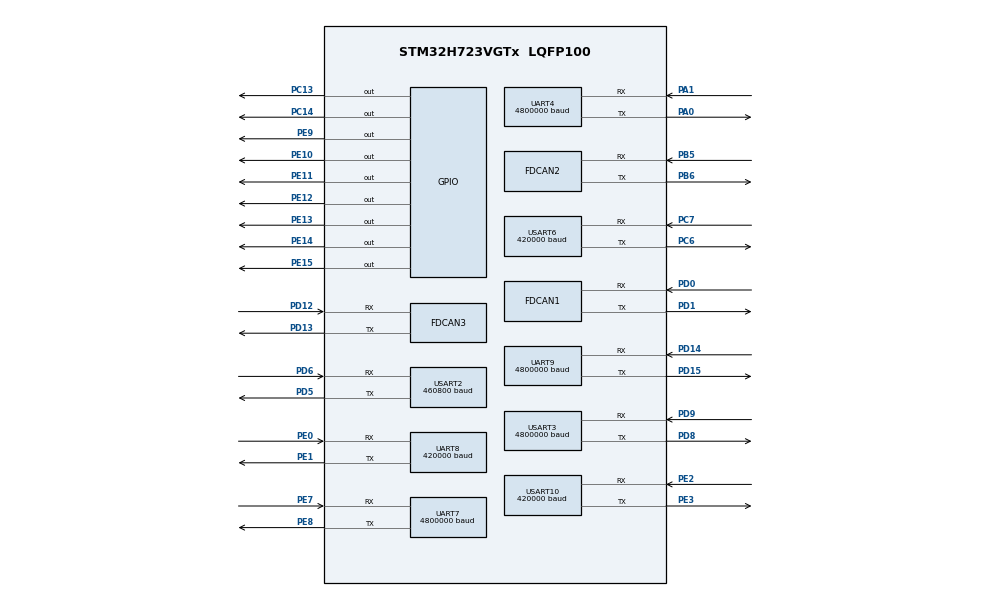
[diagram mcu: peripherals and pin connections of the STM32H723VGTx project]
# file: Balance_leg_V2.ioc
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CORTEX_M7.AccessPermission_Spec=MPU_REGION_FULL_ACCESS
CORTEX_M7.BaseAddress_Spec=0x24000000
CORTEX_M7.CPU_DCache=Enabled
CORTEX_M7.CPU_ICache=Enabled
CORTEX_M7.DisableExec_Spec=MPU_INSTRUCTION_ACCESS_ENABLE
CORTEX_M7.IsBufferable_Spec=MPU_ACCESS_BUFFERABLE
CORTEX_M7.IsCacheable_Spec=MPU_ACCESS_CACHEABLE
CORTEX_M7.IsShareable_Spec=MPU_ACCESS_SHAREABLE
CORTEX_M7.Size_Spec=MPU_REGION_SIZE_512KB
CORTEX_M7.SubRegionDisable_Spec=0x00
CORTEX_M7.TypeExtField_Spec=MPU_TEX_LEVEL1
CORTEX_M7.default_mode_Activation=1
Dma.Request0=USART10_RX
Dma.Request1=USART2_RX
Dma.Request10=UART8_RX
Dma.Request11=UART8_TX
Dma.Request2=USART3_RX
Dma.Request3=USART3_TX
Dma.Request4=UART9_RX
Dma.Request5=UART9_TX
Dma.Request6=UART7_RX
Dma.Request7=UART7_TX
Dma.Request8=UART4_RX
Dma.Request9=UART4_TX
Dma.UART4_RX.8.Direction=DMA_PERIPH_TO_MEMORY
Dma.UART4_RX.8.EventEnable=DISABLE
Dma.UART4_RX.8.FIFOMode=DMA_FIFOMODE_DISABLE
Dma.UART4_RX.8.Instance=DMA1_Stream7
Dma.UART4_RX.8.MemDataAlignment=DMA_MDATAALIGN_BYTE
Dma.UART4_RX.8.MemInc=DMA_MINC_ENABLE
Dma.UART4_RX.8.Mode=DMA_NORMAL
Dma.UART4_RX.8.PeriphDataAlignment=DMA_PDATAALIGN_BYTE
Dma.UART4_RX.8.PeriphInc=DMA_PINC_DISABLE
Dma.UART4_RX.8.Polarity=HAL_DMAMUX_REQ_GEN_RISING
Dma.UART4_RX.8.Priority=DMA_PRIORITY_HIGH
Dma.UART4_RX.8.RequestNumber=1
Dma.UART4_RX.8.SignalID=NONE
Dma.UART4_RX.8.SyncEnable=DISABLE
Dma.UART4_RX.8.SyncPolarity=HAL_DMAMUX_SYNC_NO_EVENT
Dma.UART4_RX.8.SyncRequestNumber=1
Dma.UART4_RX.8.SyncSignalID=NONE
Dma.UART4_TX.9.Direction=DMA_MEMORY_TO_PERIPH
Dma.UART4_TX.9.EventEnable=DISABLE
Dma.UART4_TX.9.FIFOMode=DMA_FIFOMODE_DISABLE
Dma.UART4_TX.9.Instance=DMA2_Stream1
Dma.UART4_TX.9.MemDataAlignment=DMA_MDATAALIGN_BYTE
Dma.UART4_TX.9.MemInc=DMA_MINC_ENABLE
Dma.UART4_TX.9.Mode=DMA_NORMAL
Dma.UART4_TX.9.PeriphDataAlignment=DMA_PDATAALIGN_BYTE
Dma.UART4_TX.9.PeriphInc=DMA_PINC_DISABLE
Dma.UART4_TX.9.Polarity=HAL_DMAMUX_REQ_GEN_RISING
Dma.UART4_TX.9.Priority=DMA_PRIORITY_HIGH
Dma.UART4_TX.9.RequestNumber=1
Dma.UART4_TX.9.SignalID=NONE
Dma.UART4_TX.9.SyncEnable=DISABLE
Dma.UART4_TX.9.SyncPolarity=HAL_DMAMUX_SYNC_NO_EVENT
Dma.UART4_TX.9.SyncRequestNumber=1
Dma.UART4_TX.9.SyncSignalID=NONE
Dma.UART7_RX.6.Direction=DMA_PERIPH_TO_MEMORY
Dma.UART7_RX.6.EventEnable=DISABLE
Dma.UART7_RX.6.FIFOMode=DMA_FIFOMODE_DISABLE
Dma.UART7_RX.6.Instance=DMA1_Stream5
Dma.UART7_RX.6.MemDataAlignment=DMA_MDATAALIGN_BYTE
Dma.UART7_RX.6.MemInc=DMA_MINC_ENABLE
Dma.UART7_RX.6.Mode=DMA_NORMAL
Dma.UART7_RX.6.PeriphDataAlignment=DMA_PDATAALIGN_BYTE
Dma.UART7_RX.6.PeriphInc=DMA_PINC_DISABLE
Dma.UART7_RX.6.Polarity=HAL_DMAMUX_REQ_GEN_RISING
Dma.UART7_RX.6.Priority=DMA_PRIORITY_HIGH
Dma.UART7_RX.6.RequestNumber=1
Dma.UART7_RX.6.SignalID=NONE
Dma.UART7_RX.6.SyncEnable=DISABLE
Dma.UART7_RX.6.SyncPolarity=HAL_DMAMUX_SYNC_NO_EVENT
Dma.UART7_RX.6.SyncRequestNumber=1
Dma.UART7_RX.6.SyncSignalID=NONE
Dma.UART7_TX.7.Direction=DMA_MEMORY_TO_PERIPH
Dma.UART7_TX.7.EventEnable=DISABLE
Dma.UART7_TX.7.FIFOMode=DMA_FIFOMODE_DISABLE
Dma.UART7_TX.7.Instance=DMA1_Stream6
Dma.UART7_TX.7.MemDataAlignment=DMA_MDATAALIGN_BYTE
Dma.UART7_TX.7.MemInc=DMA_MINC_ENABLE
Dma.UART7_TX.7.Mode=DMA_NORMAL
Dma.UART7_TX.7.PeriphDataAlignment=DMA_PDATAALIGN_BYTE
Dma.UART7_TX.7.PeriphInc=DMA_PINC_DISABLE
Dma.UART7_TX.7.Polarity=HAL_DMAMUX_REQ_GEN_RISING
Dma.UART7_TX.7.Priority=DMA_PRIORITY_HIGH
Dma.UART7_TX.7.RequestNumber=1
Dma.UART7_TX.7.SignalID=NONE
Dma.UART7_TX.7.SyncEnable=DISABLE
Dma.UART7_TX.7.SyncPolarity=HAL_DMAMUX_SYNC_NO_EVENT
Dma.UART7_TX.7.SyncRequestNumber=1
Dma.UART7_TX.7.SyncSignalID=NONE
Dma.UART8_RX.10.Direction=DMA_PERIPH_TO_MEMORY
Dma.UART8_RX.10.EventEnable=DISABLE
Dma.UART8_RX.10.FIFOMode=DMA_FIFOMODE_DISABLE
Dma.UART8_RX.10.Instance=DMA2_Stream2
Dma.UART8_RX.10.MemDataAlignment=DMA_MDATAALIGN_BYTE
Dma.UART8_RX.10.MemInc=DMA_MINC_ENABLE
Dma.UART8_RX.10.Mode=DMA_NORMAL
Dma.UART8_RX.10.PeriphDataAlignment=DMA_PDATAALIGN_BYTE
Dma.UART8_RX.10.PeriphInc=DMA_PINC_DISABLE
Dma.UART8_RX.10.Polarity=HAL_DMAMUX_REQ_GEN_RISING
Dma.UART8_RX.10.Priority=DMA_PRIORITY_LOW
Dma.UART8_RX.10.RequestNumber=1
Dma.UART8_RX.10.SignalID=NONE
Dma.UART8_RX.10.SyncEnable=DISABLE
Dma.UART8_RX.10.SyncPolarity=HAL_DMAMUX_SYNC_NO_EVENT
Dma.UART8_RX.10.SyncRequestNumber=1
Dma.UART8_RX.10.SyncSignalID=NONE
Dma.UART8_TX.11.Direction=DMA_MEMORY_TO_PERIPH
Dma.UART8_TX.11.EventEnable=DISABLE
Dma.UART8_TX.11.FIFOMode=DMA_FIFOMODE_DISABLE
Dma.UART8_TX.11.Instance=DMA2_Stream3
Dma.UART8_TX.11.MemDataAlignment=DMA_MDATAALIGN_BYTE
Dma.UART8_TX.11.MemInc=DMA_MINC_ENABLE
Dma.UART8_TX.11.Mode=DMA_NORMAL
Dma.UART8_TX.11.PeriphDataAlignment=DMA_PDATAALIGN_BYTE
Dma.UART8_TX.11.PeriphInc=DMA_PINC_DISABLE
Dma.UART8_TX.11.Polarity=HAL_DMAMUX_REQ_GEN_RISING
Dma.UART8_TX.11.Priority=DMA_PRIORITY_LOW
Dma.UART8_TX.11.RequestNumber=1
Dma.UART8_TX.11.SignalID=NONE
Dma.UART8_TX.11.SyncEnable=DISABLE
Dma.UART8_TX.11.SyncPolarity=HAL_DMAMUX_SYNC_NO_EVENT
Dma.UART8_TX.11.SyncRequestNumber=1
Dma.UART8_TX.11.SyncSignalID=NONE
Dma.UART9_RX.4.Direction=DMA_PERIPH_TO_MEMORY
Dma.UART9_RX.4.EventEnable=DISABLE
Dma.UART9_RX.4.FIFOMode=DMA_FIFOMODE_DISABLE
Dma.UART9_RX.4.Instance=DMA1_Stream3
Dma.UART9_RX.4.MemDataAlignment=DMA_MDATAALIGN_BYTE
Dma.UART9_RX.4.MemInc=DMA_MINC_ENABLE
Dma.UART9_RX.4.Mode=DMA_NORMAL
Dma.UART9_RX.4.PeriphDataAlignment=DMA_PDATAALIGN_BYTE
Dma.UART9_RX.4.PeriphInc=DMA_PINC_DISABLE
Dma.UART9_RX.4.Polarity=HAL_DMAMUX_REQ_GEN_RISING
Dma.UART9_RX.4.Priority=DMA_PRIORITY_HIGH
Dma.UART9_RX.4.RequestNumber=1
Dma.UART9_RX.4.SignalID=NONE
Dma.UART9_RX.4.SyncEnable=DISABLE
Dma.UART9_RX.4.SyncPolarity=HAL_DMAMUX_SYNC_NO_EVENT
Dma.UART9_RX.4.SyncRequestNumber=1
Dma.UART9_RX.4.SyncSignalID=NONE
Dma.UART9_TX.5.Direction=DMA_MEMORY_TO_PERIPH
Dma.UART9_TX.5.EventEnable=DISABLE
Dma.UART9_TX.5.FIFOMode=DMA_FIFOMODE_DISABLE
Dma.UART9_TX.5.Instance=DMA1_Stream4
Dma.UART9_TX.5.MemDataAlignment=DMA_MDATAALIGN_BYTE
Dma.UART9_TX.5.MemInc=DMA_MINC_ENABLE
Dma.UART9_TX.5.Mode=DMA_NORMAL
Dma.UART9_TX.5.PeriphDataAlignment=DMA_PDATAALIGN_BYTE
Dma.UART9_TX.5.PeriphInc=DMA_PINC_DISABLE
Dma.UART9_TX.5.Polarity=HAL_DMAMUX_REQ_GEN_RISING
Dma.UART9_TX.5.Priority=DMA_PRIORITY_HIGH
Dma.UART9_TX.5.RequestNumber=1
Dma.UART9_TX.5.SignalID=NONE
Dma.UART9_TX.5.SyncEnable=DISABLE
Dma.UART9_TX.5.SyncPolarity=HAL_DMAMUX_SYNC_NO_EVENT
Dma.UART9_TX.5.SyncRequestNumber=1
Dma.UART9_TX.5.SyncSignalID=NONE
Dma.USART10_RX.0.Direction=DMA_PERIPH_TO_MEMORY
Dma.USART10_RX.0.EventEnable=DISABLE
Dma.USART10_RX.0.FIFOMode=DMA_FIFOMODE_DISABLE
Dma.USART10_RX.0.Instance=DMA1_Stream0
Dma.USART10_RX.0.MemDataAlignment=DMA_MDATAALIGN_BYTE
Dma.USART10_RX.0.MemInc=DMA_MINC_ENABLE
Dma.USART10_RX.0.Mode=DMA_NORMAL
Dma.USART10_RX.0.PeriphDataAlignment=DMA_PDATAALIGN_BYTE
Dma.USART10_RX.0.PeriphInc=DMA_PINC_DISABLE
Dma.USART10_RX.0.Polarity=HAL_DMAMUX_REQ_GEN_RISING
Dma.USART10_RX.0.Priority=DMA_PRIORITY_MEDIUM
Dma.USART10_RX.0.RequestNumber=1
Dma.USART10_RX.0.SignalID=NONE
Dma.USART10_RX.0.SyncEnable=DISABLE
Dma.USART10_RX.0.SyncPolarity=HAL_DMAMUX_SYNC_NO_EVENT
Dma.USART10_RX.0.SyncRequestNumber=1
Dma.USART10_RX.0.SyncSignalID=NONE
Dma.USART2_RX.1.Direction=DMA_PERIPH_TO_MEMORY
Dma.USART2_RX.1.EventEnable=DISABLE
Dma.USART2_RX.1.FIFOMode=DMA_FIFOMODE_DISABLE
Dma.USART2_RX.1.Instance=DMA2_Stream0
Dma.USART2_RX.1.MemDataAlignment=DMA_MDATAALIGN_BYTE
Dma.USART2_RX.1.MemInc=DMA_MINC_ENABLE
Dma.USART2_RX.1.Mode=DMA_NORMAL
Dma.USART2_RX.1.PeriphDataAlignment=DMA_PDATAALIGN_BYTE
Dma.USART2_RX.1.PeriphInc=DMA_PINC_DISABLE
Dma.USART2_RX.1.Polarity=HAL_DMAMUX_REQ_GEN_RISING
Dma.USART2_RX.1.Priority=DMA_PRIORITY_VERY_HIGH
Dma.USART2_RX.1.RequestNumber=1
Dma.USART2_RX.1.SignalID=NONE
Dma.USART2_RX.1.SyncEnable=DISABLE
Dma.USART2_RX.1.SyncPolarity=HAL_DMAMUX_SYNC_NO_EVENT
Dma.USART2_RX.1.SyncRequestNumber=1
Dma.USART2_RX.1.SyncSignalID=NONE
Dma.USART3_RX.2.Direction=DMA_PERIPH_TO_MEMORY
Dma.USART3_RX.2.EventEnable=DISABLE
Dma.USART3_RX.2.FIFOMode=DMA_FIFOMODE_DISABLE
Dma.USART3_RX.2.Instance=DMA1_Stream1
Dma.USART3_RX.2.MemDataAlignment=DMA_MDATAALIGN_BYTE
Dma.USART3_RX.2.MemInc=DMA_MINC_ENABLE
Dma.USART3_RX.2.Mode=DMA_NORMAL
Dma.USART3_RX.2.PeriphDataAlignment=DMA_PDATAALIGN_BYTE
Dma.USART3_RX.2.PeriphInc=DMA_PINC_DISABLE
Dma.USART3_RX.2.Polarity=HAL_DMAMUX_REQ_GEN_RISING
Dma.USART3_RX.2.Priority=DMA_PRIORITY_HIGH
Dma.USART3_RX.2.RequestNumber=1
Dma.USART3_RX.2.SignalID=NONE
Dma.USART3_RX.2.SyncEnable=DISABLE
Dma.USART3_RX.2.SyncPolarity=HAL_DMAMUX_SYNC_NO_EVENT
Dma.USART3_RX.2.SyncRequestNumber=1
Dma.USART3_RX.2.SyncSignalID=NONE
Dma.USART3_TX.3.Direction=DMA_MEMORY_TO_PERIPH
Dma.USART3_TX.3.EventEnable=DISABLE
Dma.USART3_TX.3.FIFOMode=DMA_FIFOMODE_DISABLE
Dma.USART3_TX.3.Instance=DMA1_Stream2
Dma.USART3_TX.3.MemDataAlignment=DMA_MDATAALIGN_BYTE
Dma.USART3_TX.3.MemInc=DMA_MINC_ENABLE
Dma.USART3_TX.3.Mode=DMA_NORMAL
Dma.USART3_TX.3.PeriphDataAlignment=DMA_PDATAALIGN_BYTE
Dma.USART3_TX.3.PeriphInc=DMA_PINC_DISABLE
Dma.USART3_TX.3.Polarity=HAL_DMAMUX_REQ_GEN_RISING
Dma.USART3_TX.3.Priority=DMA_PRIORITY_HIGH
Dma.USART3_TX.3.RequestNumber=1
Dma.USART3_TX.3.SignalID=NONE
Dma.USART3_TX.3.SyncEnable=DISABLE
Dma.USART3_TX.3.SyncPolarity=HAL_DMAMUX_SYNC_NO_EVENT
Dma.USART3_TX.3.SyncRequestNumber=1
Dma.USART3_TX.3.SyncSignalID=NONE
FDCAN1.CalculateBaudRateNominal=1000000
FDCAN1.CalculateTimeBitNominal=1000
FDCAN1.CalculateTimeQuantumNominal=40.0
FDCAN1.DataPrescaler=4
FDCAN1.DataTimeSeg1=19
FDCAN1.DataTimeSeg2=5
FDCAN1.ExtFiltersNbr=5
FDCAN1.NominalPrescaler=4
FDCAN1.NominalTimeSeg1=19
FDCAN1.NominalTimeSeg2=5
FDCAN1.RxFifo0ElmtSize=FDCAN_DATA_BYTES_24
FDCAN1.RxFifo0ElmtsNbr=4
FDCAN1.RxFifo1ElmtSize=FDCAN_DATA_BYTES_24
FDCAN1.StdFiltersNbr=5
FDCAN1.TxElmtSize=FDCAN_DATA_BYTES_24
FDCAN1.TxFifoQueueElmtsNbr=8
FDCAN2.CalculateBaudRateNominal=1000000
FDCAN2.CalculateTimeBitNominal=1000
FDCAN2.CalculateTimeQuantumNominal=50.0
FDCAN2.DataPrescaler=5
FDCAN2.DataTimeSeg1=14
FDCAN2.DataTimeSeg2=5
FDCAN2.ExtFiltersNbr=5
FDCAN2.MessageRAMOffset=854
FDCAN2.NominalPrescaler=5
FDCAN2.NominalTimeSeg1=14
FDCAN2.NominalTimeSeg2=5
FDCAN2.RxFifo0ElmtSize=FDCAN_DATA_BYTES_8
FDCAN2.RxFifo0ElmtsNbr=0
FDCAN2.RxFifo1ElmtSize=FDCAN_DATA_BYTES_24
FDCAN2.RxFifo1ElmtsNbr=4
FDCAN2.StdFiltersNbr=5
FDCAN2.TxElmtSize=FDCAN_DATA_BYTES_16
FDCAN2.TxFifoQueueElmtsNbr=4
FDCAN3.CalculateBaudRateNominal=1000000
FDCAN3.CalculateTimeBitNominal=1000
FDCAN3.CalculateTimeQuantumNominal=50.0
FDCAN3.DataPrescaler=5
FDCAN3.DataTimeSeg1=14
FDCAN3.DataTimeSeg2=5
FDCAN3.ExtFiltersNbr=5
FDCAN3.MessageRAMOffset=1709
FDCAN3.NominalPrescaler=5
FDCAN3.NominalTimeSeg1=14
FDCAN3.NominalTimeSeg2=5
FDCAN3.RxFifo0ElmtsNbr=2
FDCAN3.StdFiltersNbr=5
FDCAN3.TxFifoQueueElmtsNbr=3
Mcu.Family=STM32H7
Mcu.Name=STM32H723VGTx
Mcu.Package=LQFP100
NVIC.DMA1_Stream0_IRQn=true\:0\:0\:true\:false\:true\:false\:true\:true
NVIC.DMA1_Stream1_IRQn=true\:4\:0\:true\:false\:true\:false\:true\:true
NVIC.DMA1_Stream2_IRQn=true\:4\:0\:true\:false\:true\:false\:true\:true
NVIC.DMA1_Stream3_IRQn=true\:5\:0\:true\:false\:true\:false\:true\:true
NVIC.DMA1_Stream4_IRQn=true\:5\:0\:true\:false\:true\:false\:true\:true
NVIC.DMA1_Stream5_IRQn=true\:3\:0\:true\:false\:true\:false\:true\:true
NVIC.DMA1_Stream6_IRQn=true\:3\:0\:true\:false\:true\:false\:true\:true
NVIC.DMA1_Stream7_IRQn=true\:2\:0\:true\:false\:true\:false\:true\:true
NVIC.DMA2_Stream0_IRQn=true\:1\:0\:true\:false\:true\:false\:true\:true
NVIC.DMA2_Stream1_IRQn=true\:2\:0\:true\:false\:true\:false\:true\:true
NVIC.DMA2_Stream2_IRQn=true\:0\:0\:false\:false\:true\:false\:true\:true
NVIC.DMA2_Stream3_IRQn=true\:0\:0\:false\:false\:true\:false\:true\:true
NVIC.FDCAN1_IT0_IRQn=true\:2\:0\:true\:false\:true\:true\:true\:true
NVIC.FDCAN2_IT0_IRQn=true\:1\:0\:true\:false\:true\:true\:true\:true
NVIC.FDCAN3_IT0_IRQn=true\:1\:0\:true\:false\:true\:true\:true\:true
NVIC.PriorityGroup=NVIC_PRIORITYGROUP_4
NVIC.TIM8_TRG_COM_TIM14_IRQn=true\:0\:0\:false\:false\:true\:true\:true\:true
NVIC.UART4_IRQn=true\:2\:0\:true\:false\:true\:true\:true\:true
NVIC.UART7_IRQn=true\:2\:0\:true\:false\:true\:true\:true\:true
NVIC.UART8_IRQn=true\:4\:0\:true\:false\:true\:true\:true\:true
NVIC.UART9_IRQn=true\:3\:0\:true\:false\:true\:true\:true\:true
NVIC.USART10_IRQn=true\:0\:0\:true\:false\:true\:true\:true\:true
NVIC.USART2_IRQn=true\:1\:0\:true\:false\:true\:true\:true\:true
NVIC.USART3_IRQn=true\:3\:0\:true\:false\:true\:true\:true\:true
PA0.GPIO_Speed=GPIO_SPEED_FREQ_VERY_HIGH
PA0.Mode=Asynchronous
PA0.Signal=UART4_TX
PA1.GPIO_Speed=GPIO_SPEED_FREQ_VERY_HIGH
PA1.Mode=Asynchronous
PA1.Signal=UART4_RX
PA13(JTMS/SWDIO).Mode=Serial_Wire
PA13(JTMS/SWDIO).Signal=DEBUG_JTMS-SWDIO
PA14(JTCK/SWCLK).Mode=Serial_Wire
PA14(JTCK/SWCLK).Signal=DEBUG_JTCK-SWCLK
PB5.Mode=FDCAN_Activate
PB5.Signal=FDCAN2_RX
PB6.Mode=FDCAN_Activate
PB6.Signal=FDCAN2_TX
PC13.PinState=GPIO_PIN_SET
PC13.Signal=GPIO_Output
PC14-OSC32_IN.PinState=GPIO_PIN_SET
PC14-OSC32_IN.Signal=GPIO_Output
PC6.GPIO_Speed=GPIO_SPEED_FREQ_VERY_HIGH
PC6.Mode=Asynchronous
PC6.Signal=USART6_TX
PC7.GPIO_Speed=GPIO_SPEED_FREQ_VERY_HIGH
PC7.Mode=Asynchronous
PC7.Signal=USART6_RX
PD0.Mode=FDCAN_Activate
PD0.Signal=FDCAN1_RX
PD1.Mode=FDCAN_Activate
PD1.Signal=FDCAN1_TX
PD12.Mode=FDCAN_Activate
PD12.Signal=FDCAN3_RX
PD13.Mode=FDCAN_Activate
PD13.Signal=FDCAN3_TX
PD14.GPIO_Speed=GPIO_SPEED_FREQ_VERY_HIGH
PD14.Mode=Asynchronous
PD14.Signal=UART9_RX
PD15.GPIO_Speed=GPIO_SPEED_FREQ_VERY_HIGH
PD15.Mode=Asynchronous
PD15.Signal=UART9_TX
PD5.GPIO_Speed=GPIO_SPEED_FREQ_VERY_HIGH
PD5.Mode=Asynchronous
PD5.Signal=USART2_TX
PD6.GPIO_Speed=GPIO_SPEED_FREQ_VERY_HIGH
PD6.Mode=Asynchronous
PD6.Signal=USART2_RX
PD8.GPIO_Speed=GPIO_SPEED_FREQ_VERY_HIGH
PD8.Mode=Asynchronous
PD8.Signal=USART3_TX
PD9.GPIO_Speed=GPIO_SPEED_FREQ_VERY_HIGH
PD9.Mode=Asynchronous
PD9.Signal=USART3_RX
PE0.Mode=Asynchronous
PE0.Signal=UART8_RX
PE1.Mode=Asynchronous
PE1.Signal=UART8_TX
PE10.GPIO_Speed=GPIO_SPEED_FREQ_HIGH
PE10.Signal=GPIO_Output
PE11.GPIO_Speed=GPIO_SPEED_FREQ_HIGH
PE11.Signal=GPIO_Output
PE12.GPIO_Speed=GPIO_SPEED_FREQ_HIGH
PE12.Signal=GPIO_Output
PE13.GPIO_Speed=GPIO_SPEED_FREQ_HIGH
PE13.Signal=GPIO_Output
PE14.GPIO_Speed=GPIO_SPEED_FREQ_HIGH
PE14.Signal=GPIO_Output
PE15.GPIO_Speed=GPIO_SPEED_FREQ_HIGH
PE15.Signal=GPIO_Output
PE2.GPIO_Speed=GPIO_SPEED_FREQ_VERY_HIGH
PE2.Mode=Asynchronous
PE2.Signal=USART10_RX
PE3.GPIO_Speed=GPIO_SPEED_FREQ_VERY_HIGH
PE3.Mode=Asynchronous
PE3.Signal=USART10_TX
PE7.GPIO_Speed=GPIO_SPEED_FREQ_VERY_HIGH
PE7.Mode=Asynchronous
PE7.Signal=UART7_RX
PE8.GPIO_Speed=GPIO_SPEED_FREQ_VERY_HIGH
PE8.Mode=Asynchronous
PE8.Signal=UART7_TX
PE9.GPIO_Speed=GPIO_SPEED_FREQ_HIGH
PE9.Signal=GPIO_Output
PH0-OSC_IN.Mode=HSE-External-Oscillator
PH0-OSC_IN.Signal=RCC_OSC_IN
PH1-OSC_OUT.Mode=HSE-External-Oscillator
PH1-OSC_OUT.Signal=RCC_OSC_OUT
ProjectManager.HeapSize=0x400
ProjectManager.StackSize=0x400
ProjectManager.TargetToolchain=STM32CubeIDE
RCC.ADCFreq_Value=100000000
RCC.APB1Freq_Value=120000000
RCC.APB2Freq_Value=120000000
RCC.APB3Freq_Value=120000000
RCC.APB4Freq_Value=120000000
RCC.CortexFreq_Value=480000000
RCC.D1PPRE=RCC_APB3_DIV2
RCC.D2PPRE1=RCC_APB1_DIV2
RCC.D2PPRE2=RCC_APB2_DIV2
RCC.D3PPRE=RCC_APB4_DIV2
RCC.DIVM1=2
RCC.DIVM2=24
RCC.DIVN1=40
RCC.DIVN2=200
RCC.DIVP1=1
RCC.FDCANCLockSelection=RCC_FDCANCLKSOURCE_PLL2
RCC.HCLKFreq_Value=240000000
RCC.HPRE=RCC_HCLK_DIV2
RCC.HSE_VALUE=24000000
RCC.PLL2FRACN=0
RCC.PLL3FRACN=0
RCC.PLLFRACN=0
RCC.PLLSourceVirtual=RCC_PLLSOURCE_HSE
RCC.SYSCLKFreq_VALUE=480000000
RCC.SYSCLKSource=RCC_SYSCLKSOURCE_PLLCLK
RCC.USBFreq_Value=240000000
STMicroelectronics.X-CUBE-ALGOBUILD.1.4.0.LibraryCcDSPOoLibraryJjDSPOoLibrary=true
TIM14.Period=1000-1
TIM14.Prescaler=240-1
UART4.BaudRate=4800000
UART7.BaudRate=4800000
UART8.BaudRate=420000
UART9.BaudRate=4800000
USART10.BaudRate=420000
USART10.VirtualMode=VM_ASYNC
USART2.BaudRate=460800
USART2.DMADisableonRxErrorParam=ADVFEATURE_DMA_ENABLEONRXERROR
USART2.Mode=MODE_TX_RX
USART2.OverrunDisableParam=ADVFEATURE_OVERRUN_ENABLE
USART2.VirtualMode-Asynchronous=VM_ASYNC
USART3.BaudRate=4800000
USART3.VirtualMode-Asynchronous=VM_ASYNC
USART6.BaudRate=420000
USART6.VirtualMode=VM_ASYNC
VP_MEMORYMAP_VS_MEMORYMAP.Mode=CurAppReg
VP_STMicroelectronics.X-CUBE-ALGOBUILD_VS_DSPOoLibraryJjLibrary_1.4.0_1.4.0.Mode=DSPOoLibraryJjLibrary
VP_TIM14_VS_ClockSourceINT.Mode=Enable_Timer
board=custom

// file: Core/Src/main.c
/* USER CODE BEGIN Header */
/**
  ******************************************************************************
  * @file           : main.c
  * @brief          : Main program body
  ******************************************************************************
  * @attention
  *
  * Copyright (c) 2024 STMicroelectronics.
  * All rights reserved.
  *
  * This software is licensed under terms that can be found in the LICENSE file
  * in the root directory of this software component.
  * If no LICENSE file comes with this software, it is provided AS-IS.
  *
  ******************************************************************************
  */
/* USER CODE END Header */
#include "main.h"
#include "dma.h"
#include "fdcan.h"
#include "memorymap.h"
#include "tim.h"
#include "usart.h"
#include "gpio.h"

/* USER CODE BEGIN Includes */
#include "Chassis_R.h"
/* USER CODE END Includes */

void SystemClock_Config(void);
void PeriphCommonClock_Config(void);
static void MPU_Config(void);

int main(void)
{

  /* MPU Configuration--------------------------------------------------------*/
  MPU_Config();

  /* Enable the CPU Cache */

  /* Enable I-Cache---------------------------------------------------------*/
  SCB_EnableICache();

  /* Enable D-Cache---------------------------------------------------------*/
  SCB_EnableDCache();

  /* MCU Configuration--------------------------------------------------------*/

  /* Reset of all peripherals, Initializes the Flash interface and the Systick. */
  HAL_Init();

  /* Configure the system clock */
  SystemClock_Config();

  /* Configure the peripherals common clocks */
  PeriphCommonClock_Config();

  /* Initialize all configured peripherals */
  MX_GPIO_Init();
  MX_DMA_Init();
  MX_USART6_UART_Init();
  MX_FDCAN1_Init();
  MX_FDCAN2_Init();
  MX_FDCAN3_Init();
  MX_USART10_UART_Init();
  MX_TIM14_Init();
  MX_USART3_UART_Init();
  MX_USART2_UART_Init();
  MX_UART9_Init();
  MX_UART4_Init();
  MX_UART7_Init();
  MX_UART8_Init();
  /* USER CODE BEGIN 2 */
  HardwareConfig();
  /* USER CODE END 2 */

  /* Infinite loop */
  /* USER CODE BEGIN WHILE */
  while (1)
  {
      printf("%d,%f,%f,%f\n", hi91_data.FPS,hi91_data.total_yaw,-hi91_data.roll,hi91_data.pitch);
//      printf("%d,%d,%f,%f,%f,%f,%d,%d,%d,%d,%d,%d,%d,%d,%d\n", hi91_data.FPS,elrs_data.FPS,elrs_data.Left_X,elrs_data.Left_Y,elrs_data.Right_X,elrs_data.Right_Y,elrs_data.A,elrs_data.B,
//      elrs_data.C,elrs_data.D,elrs_data.E,elrs_data.F,elrs_data.S1,elrs_data.S2,elrs_data.isOnline);
//      printf("%f,%f,%f\n", A1_Motor[1].motor_recv.Pos,A1_Motor[0].motor_recv.W,A1_Motor[1].motor_recv.W);
//      printf("%d,%f,%d,%d,%d,%f\n", A1_Motor[A1_Motor_left_1].motor_recv.FPS,A1_Motor[A1_Motor_left_2].motor_recv.original_Pos,A1_Motor[A1_Motor_right_1].motor_recv.FPS,A1_Motor[A1_Motor_right_2].motor_recv.FPS,hi91_data.FPS,elrs_data.Left_Y);
//      printf("%f,%f,%f,%f\n",A1_Motor[A1_Motor_left_1].motor_recv.original_Pos,A1_Motor[A1_Motor_left_2].motor_recv.original_Pos,A1_Motor[A1_Motor_right_1].motor_recv.original_Pos,A1_Motor[A1_Motor_right_2].motor_recv.original_Pos);
//      printf("%f,%f,%f,%f,%f\n",right.L0,chassis_move.leg_set,right.FN,right.F0,A1_Motor[A1_Motor_right_2].motor_send.T);
//      printf("%f,%f,%f,%f,%f\n",chassis_move.x_filter,chassis_move.x_set,chassis_move.v_filter,chassis_move.v_set,right.L0);
      HAL_Delay(10);
    /* USER CODE END WHILE */

  }
}

void SystemClock_Config(void)
{
  RCC_OscInitTypeDef RCC_OscInitStruct = {0};
  RCC_ClkInitTypeDef RCC_ClkInitStruct = {0};

  /** Supply configuration update enable
  */
  HAL_PWREx_ConfigSupply(PWR_LDO_SUPPLY);

  /** Configure the main internal regulator output voltage
  */
  __HAL_PWR_VOLTAGESCALING_CONFIG(PWR_REGULATOR_VOLTAGE_SCALE0);

  while(!__HAL_PWR_GET_FLAG(PWR_FLAG_VOSRDY)) {}

  /** Initializes the RCC Oscillators according to the specified parameters
  * in the RCC_OscInitTypeDef structure.
  */
  RCC_OscInitStruct.OscillatorType = RCC_OSCILLATORTYPE_HSE;
  RCC_OscInitStruct.HSEState = RCC_HSE_ON;
  RCC_OscInitStruct.PLL.PLLState = RCC_PLL_ON;
  RCC_OscInitStruct.PLL.PLLSource = RCC_PLLSOURCE_HSE;
  RCC_OscInitStruct.PLL.PLLM = 2;
  RCC_OscInitStruct.PLL.PLLN = 40;
  RCC_OscInitStruct.PLL.PLLP = 1;
  RCC_OscInitStruct.PLL.PLLQ = 2;
  RCC_OscInitStruct.PLL.PLLR = 2;
  RCC_OscInitStruct.PLL.PLLRGE = RCC_PLL1VCIRANGE_3;
  RCC_OscInitStruct.PLL.PLLVCOSEL = RCC_PLL1VCOWIDE;
  RCC_OscInitStruct.PLL.PLLFRACN = 0;
  if (HAL_RCC_OscConfig(&RCC_OscInitStruct) != HAL_OK)
  {
    Error_Handler();
  }

  /** Initializes the CPU, AHB and APB buses clocks
  */
  RCC_ClkInitStruct.ClockType = RCC_CLOCKTYPE_HCLK|RCC_CLOCKTYPE_SYSCLK
                              |RCC_CLOCKTYPE_PCLK1|RCC_CLOCKTYPE_PCLK2
                              |RCC_CLOCKTYPE_D3PCLK1|RCC_CLOCKTYPE_D1PCLK1;
  RCC_ClkInitStruct.SYSCLKSource = RCC_SYSCLKSOURCE_PLLCLK;
  RCC_ClkInitStruct.SYSCLKDivider = RCC_SYSCLK_DIV1;
  RCC_ClkInitStruct.AHBCLKDivider = RCC_HCLK_DIV2;
  RCC_ClkInitStruct.APB3CLKDivider = RCC_APB3_DIV2;
  RCC_ClkInitStruct.APB1CLKDivider = RCC_APB1_DIV2;
  RCC_ClkInitStruct.APB2CLKDivider = RCC_APB2_DIV2;
  RCC_ClkInitStruct.APB4CLKDivider = RCC_APB4_DIV2;

  if (HAL_RCC_ClockConfig(&RCC_ClkInitStruct, FLASH_LATENCY_3) != HAL_OK)
  {
    Error_Handler();
  }
}

void PeriphCommonClock_Config(void)
{
  RCC_PeriphCLKInitTypeDef PeriphClkInitStruct = {0};

  /** Initializes the peripherals clock
  */
  PeriphClkInitStruct.PeriphClockSelection = RCC_PERIPHCLK_FDCAN;
  PeriphClkInitStruct.PLL2.PLL2M = 24;
  PeriphClkInitStruct.PLL2.PLL2N = 200;
  PeriphClkInitStruct.PLL2.PLL2P = 2;
  PeriphClkInitStruct.PLL2.PLL2Q = 2;
  PeriphClkInitStruct.PLL2.PLL2R = 2;
  PeriphClkInitStruct.PLL2.PLL2RGE = RCC_PLL2VCIRANGE_0;
  PeriphClkInitStruct.PLL2.PLL2VCOSEL = RCC_PLL2VCOMEDIUM;
  PeriphClkInitStruct.PLL2.PLL2FRACN = 0;
  PeriphClkInitStruct.FdcanClockSelection = RCC_FDCANCLKSOURCE_PLL2;
  if (HAL_RCCEx_PeriphCLKConfig(&PeriphClkInitStruct) != HAL_OK)
  {
    Error_Handler();
  }
}

 /* MPU Configuration */

void MPU_Config(void)
{
  MPU_Region_InitTypeDef MPU_InitStruct = {0};

  /* Disables the MPU */
  HAL_MPU_Disable();

  /** Initializes and configures the Region and the memory to be protected
  */
  MPU_InitStruct.Enable = MPU_REGION_ENABLE;
  MPU_InitStruct.Number = MPU_REGION_NUMBER0;
  MPU_InitStruct.BaseAddress = 0x24000000;
  MPU_InitStruct.Size = MPU_REGION_SIZE_512KB;
  MPU_InitStruct.SubRegionDisable = 0x00;
  MPU_InitStruct.TypeExtField = MPU_TEX_LEVEL1;
  MPU_InitStruct.AccessPermission = MPU_REGION_FULL_ACCESS;
  MPU_InitStruct.DisableExec = MPU_INSTRUCTION_ACCESS_ENABLE;
  MPU_InitStruct.IsShareable = MPU_ACCESS_SHAREABLE;
  MPU_InitStruct.IsCacheable = MPU_ACCESS_CACHEABLE;
  MPU_InitStruct.IsBufferable = MPU_ACCESS_BUFFERABLE;

  HAL_MPU_ConfigRegion(&MPU_InitStruct);
  /* Enables the MPU */
  HAL_MPU_Enable(MPU_PRIVILEGED_DEFAULT);

}

void Error_Handler(void)
{
  __disable_irq();
  while (1)
  {
  }
}
